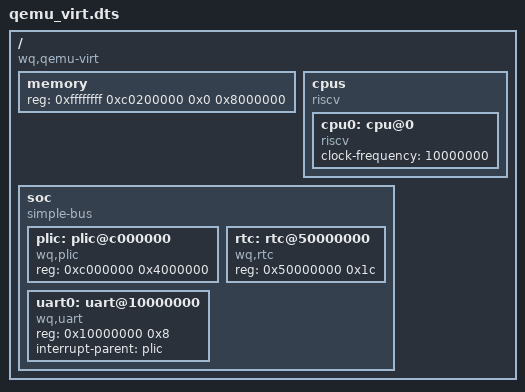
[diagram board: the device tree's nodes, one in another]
/dts-v1/;
/ {
    #address-cells = <2>;
    #size-cells = <2>;
    compatible = "wq,qemu-virt";

    memory {
        #address-cells = <1>;
        #size-cells = <1>;
        device_type = "memory";
        reg = <0xffffffff 0xc0200000 0x0 0x8000000>; /* 512MB RAM */
    };

    cpus {
        compatible = "riscv";
        #address-cells = <1>;
        #size-cells = <1>;
        cpu0: cpu@0 {
            compatible = "riscv";
            clock-frequency = <10000000>;
        };
    };

    soc {
        #address-cells = <1>;
        #size-cells = <1>;
        compatible = "simple-bus";

        plic: plic@c000000 {
            compatible = "wq,plic";
            reg = <0xc000000 0x4000000>;
        };
       
        rtc: rtc@50000000 {
            compatible = "wq,rtc";
            reg = <0x50000000 0x1c>;
        };

        uart0: uart@10000000 {
            compatible = "wq,uart";
            reg = <0x10000000 0x8>;
            interrupt-parent = <&plic>;
        };

    };
};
